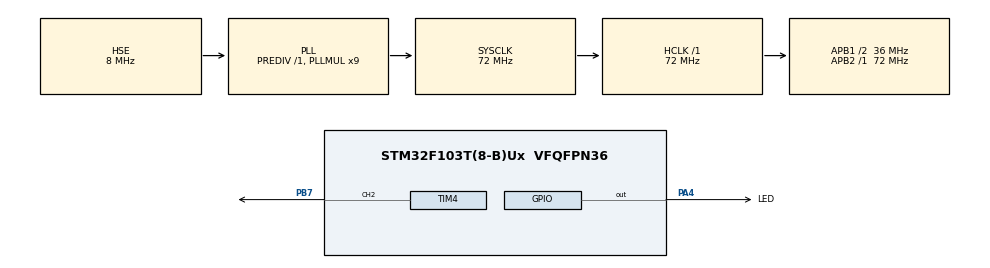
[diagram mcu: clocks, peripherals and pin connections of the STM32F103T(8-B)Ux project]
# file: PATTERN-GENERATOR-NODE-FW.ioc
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Mcu.Family=STM32F1
RCC.PLLSourceVirtual=RCC_PLLSOURCE_HSE
PD1-OSC_OUT.Mode=HSE-External-Oscillator
PD0-OSC_IN.Signal=RCC_OSC_IN
RCC.APB1CLKDivider=RCC_HCLK_DIV2
RCC.SYSCLKSource=RCC_SYSCLKSOURCE_PLLCLK
ProjectManager.StackSize=0x400
Dma.TIM4_CH2.0.PeriphInc=DMA_PINC_DISABLE
Dma.TIM4_CH2.0.Priority=DMA_PRIORITY_LOW
PD1-OSC_OUT.Signal=RCC_OSC_OUT
PA13.Signal=SYS_JTMS-SWDIO
ProjectManager.TargetToolchain=STM32CubeIDE
Dma.TIM4_CH2.0.MemInc=DMA_MINC_ENABLE
Dma.TIM4_CH2.0.Mode=DMA_NORMAL
RCC.HCLKFreq_Value=72000000
RCC.APB2TimFreq_Value=72000000
RCC.USBFreq_Value=72000000
Dma.TIM4_CH2.0.PeriphDataAlignment=DMA_PDATAALIGN_HALFWORD
RCC.AHBFreq_Value=72000000
PD0-OSC_IN.Mode=HSE-External-Oscillator
PB7.GPIO_ModeDefaultPP=GPIO_MODE_AF_PP
board=custom
RCC.PLLMUL=RCC_PLL_MUL9
TIM4.Channel-PWM\ Generation2\ CH2=TIM_CHANNEL_2
RCC.APB2Freq_Value=72000000
PA14.Mode=Serial_Wire
SH.S_TIM4_CH2.0=TIM4_CH2,PWM Generation2 CH2
PB7.Signal=S_TIM4_CH2
TIM4.Period=90
Dma.TIM4_CH2.0.Direction=DMA_MEMORY_TO_PERIPH
PA13.Mode=Serial_Wire
Mcu.Name=STM32F103T(8-B)Ux
PA4.Signal=GPIO_Output
RCC.SYSCLKFreq_VALUE=72000000
Mcu.Package=VFQFPN36
PA14.Signal=SYS_JTCK-SWCLK
ProjectManager.HeapSize=0x200
PA4.GPIO_ModeDefaultOutputPP=GPIO_MODE_OUTPUT_PP
VP_TIM4_VS_ClockSourceINT.Mode=Internal
NVIC.PriorityGroup=NVIC_PRIORITYGROUP_4
Dma.TIM4_CH2.0.Instance=DMA1_Channel4
RCC.APB1TimFreq_Value=72000000
NVIC.DMA1_Channel4_IRQn=true\:0\:0\:false\:false\:true\:false\:true
NVIC.TIM4_IRQn=true\:0\:0\:false\:false\:true\:true\:true
Dma.Request0=TIM4_CH2
RCC.APB1Freq_Value=36000000
PA4.GPIO_Label=LED
Dma.TIM4_CH2.0.MemDataAlignment=DMA_MDATAALIGN_HALFWORD
TIM4.Pulse-PWM\ Generation2\ CH2=45
PB7.GPIO_Speed=GPIO_SPEED_FREQ_LOW

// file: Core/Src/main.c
/* USER CODE BEGIN Header */
/**
  ******************************************************************************
  * @file           : main.c
  * @brief          : Main program body
  ******************************************************************************
  * @attention
  *
  * <h2><center>&copy; Copyright (c) 2021 STMicroelectronics.
  * All rights reserved.</center></h2>
  *
  * This software component is licensed by ST under BSD 3-Clause license,
  * the "License"; You may not use this file except in compliance with the
  * License. You may obtain a copy of the License at:
  *                        opensource.org/licenses/BSD-3-Clause
  *
  ******************************************************************************
  */
/* USER CODE END Header */
#include "main.h"

/* USER CODE BEGIN Includes */
#include "leds_rgb.h"
/* USER CODE END Includes */

TIM_HandleTypeDef htim4;
DMA_HandleTypeDef hdma_tim4_ch2;

void SystemClock_Config(void);
static void MX_GPIO_Init(void);
static void MX_DMA_Init(void);
static void MX_TIM4_Init(void);

/* USER CODE BEGIN 0 */
Leds_Color_t colors;
const uint32_t RGB_PALLET[MAX_NUM_OF_LEDS] = {
/*
 *    1		2		   3		4	    	5		6		7			8		9			10		11			12		  13		14		  15 		16
 */

0xff2828, 0xff7c28, 0xffd128, 0xebff28, 0x97ff28, 0x42ff28, 0x28ffb6, 0x28d5ff, 0x28b1ff, 0x285dff, 0x4828ff, 0x9c28ff, 0xf028ff, 0xff28cb, 0xff2877, 0xc1c1c1,//0
0xff2828, 0xff7c28, 0xffd128, 0xebff28, 0x97ff28, 0x42ff28, 0x28ffb6, 0x28d5ff, 0x28b1ff, 0x285dff, 0x4828ff, 0x9c28ff, 0xf028ff, 0xff28cb, 0xff2877, 0xc1c1c1,//1
0xff2828, 0xff7c28, 0xffd128, 0xebff28, 0x97ff28, 0x42ff28, 0x28ffb6, 0x28d5ff, 0x28b1ff, 0x285dff, 0x4828ff, 0x9c28ff, 0xf028ff, 0xff28cb, 0xff2877, 0xc1c1c1,//2
0xff2828, 0xff7c28, 0xffd128, 0xebff28, 0x97ff28, 0x42ff28, 0x28ffb6, 0x28d5ff, 0x28b1ff, 0x285dff, 0x4828ff, 0x9c28ff, 0xf028ff, 0xff28cb, 0xff2877, 0xc1c1c1,//3
0xff2828, 0xff7c28, 0xffd128, 0xebff28, 0x97ff28, 0x42ff28, 0x28ffb6, 0x28d5ff, 0x28b1ff, 0x285dff, 0x4828ff, 0x9c28ff, 0xf028ff, 0xff28cb, 0xff2877, 0xc1c1c1 //4
};

/* USER CODE END 0 */

int main(void)
{

  /* MCU Configuration--------------------------------------------------------*/

  /* Reset of all peripherals, Initializes the Flash interface and the Systick. */
  HAL_Init();

  /* Configure the system clock */
  SystemClock_Config();

  /* Initialize all configured peripherals */
  MX_GPIO_Init();
  MX_DMA_Init();
  MX_TIM4_Init();
  /* USER CODE BEGIN 2 */
  for (int var = 0; var < MAX_NUM_OF_LEDS; ++var) {
//	if((var%16)<4){
//	  	colors.colors[var].shades.red   = (uint8_t)((0xff0000 & 0xff0000)>>16);
//	  	colors.colors[var].shades.green = (uint8_t)((0x00ff00 & 0xff0000)>>8);
//	  	colors.colors[var].shades.blue  = (uint8_t)((0x0000ff & 0xff0000));
//	}
//	else

  	colors.colors[var].shades.red   = (uint8_t)((0xff0000 & RGB_PALLET[var])>>16);
  	colors.colors[var].shades.green = (uint8_t)((0x00ff00 & RGB_PALLET[var])>>8);
  	colors.colors[var].shades.blue  = (uint8_t)((0x0000ff & RGB_PALLET[var]));

  }
  if(rgbLedsInit(MAX_NUM_OF_LEDS, &htim4, TIM_CHANNEL_2)== STATUS_OK){
	  HAL_GPIO_TogglePin(LED_GPIO_Port, LED_Pin);
	  	  HAL_Delay(25);
	  	  HAL_GPIO_TogglePin(LED_GPIO_Port, LED_Pin);
	  	  HAL_Delay(25);
	  	  HAL_GPIO_TogglePin(LED_GPIO_Port, LED_Pin);
	  	  HAL_Delay(25);
	  	  HAL_GPIO_TogglePin(LED_GPIO_Port, LED_Pin);
	  	  HAL_Delay(25);
	  	  HAL_GPIO_TogglePin(LED_GPIO_Port, LED_Pin);
	  	  HAL_Delay(25);
	  	  HAL_GPIO_TogglePin(LED_GPIO_Port, LED_Pin);
	  	  HAL_Delay(25);
  }
  else{
	  for(;;){
	  	  HAL_GPIO_TogglePin(LED_GPIO_Port, LED_Pin);
	  	  HAL_Delay(25);
	  	  HAL_GPIO_TogglePin(LED_GPIO_Port, LED_Pin);
	  	  HAL_Delay(25);
	  	  HAL_GPIO_TogglePin(LED_GPIO_Port, LED_Pin);
	  	  HAL_Delay(25);
	  	  HAL_GPIO_TogglePin(LED_GPIO_Port, LED_Pin);

	  	  HAL_Delay(1000);
	  }
  }
  rgbLedsMapColorToPwm(&colors);
  /* USER CODE END 2 */

  /* Infinite loop */
  /* USER CODE BEGIN WHILE */

//  uint32_t colour = 0xff2828;  // colour code for some color
//  WS2812_Send(colour);

  while (1)
  {
    /* USER CODE END WHILE */

    /* USER CODE BEGIN 3 */
	  rgbLedsStart();
	  HAL_Delay(250);

  }
  /* USER CODE END 3 */
}

void SystemClock_Config(void)
{
  RCC_OscInitTypeDef RCC_OscInitStruct = {0};
  RCC_ClkInitTypeDef RCC_ClkInitStruct = {0};

  /** Initializes the RCC Oscillators according to the specified parameters
  * in the RCC_OscInitTypeDef structure.
  */
  RCC_OscInitStruct.OscillatorType = RCC_OSCILLATORTYPE_HSE;
  RCC_OscInitStruct.HSEState = RCC_HSE_ON;
  RCC_OscInitStruct.HSEPredivValue = RCC_HSE_PREDIV_DIV1;
  RCC_OscInitStruct.HSIState = RCC_HSI_ON;
  RCC_OscInitStruct.PLL.PLLState = RCC_PLL_ON;
  RCC_OscInitStruct.PLL.PLLSource = RCC_PLLSOURCE_HSE;
  RCC_OscInitStruct.PLL.PLLMUL = RCC_PLL_MUL9;
  if (HAL_RCC_OscConfig(&RCC_OscInitStruct) != HAL_OK)
  {
    Error_Handler();
  }
  /** Initializes the CPU, AHB and APB buses clocks
  */
  RCC_ClkInitStruct.ClockType = RCC_CLOCKTYPE_HCLK|RCC_CLOCKTYPE_SYSCLK
                              |RCC_CLOCKTYPE_PCLK1|RCC_CLOCKTYPE_PCLK2;
  RCC_ClkInitStruct.SYSCLKSource = RCC_SYSCLKSOURCE_PLLCLK;
  RCC_ClkInitStruct.AHBCLKDivider = RCC_SYSCLK_DIV1;
  RCC_ClkInitStruct.APB1CLKDivider = RCC_HCLK_DIV2;
  RCC_ClkInitStruct.APB2CLKDivider = RCC_HCLK_DIV1;

  if (HAL_RCC_ClockConfig(&RCC_ClkInitStruct, FLASH_LATENCY_2) != HAL_OK)
  {
    Error_Handler();
  }
}

static void MX_TIM4_Init(void)
{

  TIM_ClockConfigTypeDef sClockSourceConfig = {0};
  TIM_MasterConfigTypeDef sMasterConfig = {0};
  TIM_OC_InitTypeDef sConfigOC = {0};

  htim4.Instance = TIM4;
  htim4.Init.Prescaler = 0;
  htim4.Init.CounterMode = TIM_COUNTERMODE_UP;
  htim4.Init.Period = 90;
  htim4.Init.ClockDivision = TIM_CLOCKDIVISION_DIV1;
  htim4.Init.AutoReloadPreload = TIM_AUTORELOAD_PRELOAD_DISABLE;
  if (HAL_TIM_Base_Init(&htim4) != HAL_OK)
  {
    Error_Handler();
  }
  sClockSourceConfig.ClockSource = TIM_CLOCKSOURCE_INTERNAL;
  if (HAL_TIM_ConfigClockSource(&htim4, &sClockSourceConfig) != HAL_OK)
  {
    Error_Handler();
  }
  if (HAL_TIM_PWM_Init(&htim4) != HAL_OK)
  {
    Error_Handler();
  }
  sMasterConfig.MasterOutputTrigger = TIM_TRGO_RESET;
  sMasterConfig.MasterSlaveMode = TIM_MASTERSLAVEMODE_DISABLE;
  if (HAL_TIMEx_MasterConfigSynchronization(&htim4, &sMasterConfig) != HAL_OK)
  {
    Error_Handler();
  }
  sConfigOC.OCMode = TIM_OCMODE_PWM1;
  sConfigOC.Pulse = 45;
  sConfigOC.OCPolarity = TIM_OCPOLARITY_HIGH;
  sConfigOC.OCFastMode = TIM_OCFAST_DISABLE;
  if (HAL_TIM_PWM_ConfigChannel(&htim4, &sConfigOC, TIM_CHANNEL_2) != HAL_OK)
  {
    Error_Handler();
  }
  HAL_TIM_MspPostInit(&htim4);

}

static void MX_DMA_Init(void)
{

  /* DMA controller clock enable */
  __HAL_RCC_DMA1_CLK_ENABLE();

  /* DMA interrupt init */
  /* DMA1_Channel4_IRQn interrupt configuration */
  HAL_NVIC_SetPriority(DMA1_Channel4_IRQn, 0, 0);
  HAL_NVIC_EnableIRQ(DMA1_Channel4_IRQn);

}

static void MX_GPIO_Init(void)
{
  GPIO_InitTypeDef GPIO_InitStruct = {0};

  /* GPIO Ports Clock Enable */
  __HAL_RCC_GPIOD_CLK_ENABLE();
  __HAL_RCC_GPIOA_CLK_ENABLE();
  __HAL_RCC_GPIOB_CLK_ENABLE();

  /*Configure GPIO pin Output Level */
  HAL_GPIO_WritePin(LED_GPIO_Port, LED_Pin, GPIO_PIN_RESET);

  /*Configure GPIO pin : LED_Pin */
  GPIO_InitStruct.Pin = LED_Pin;
  GPIO_InitStruct.Mode = GPIO_MODE_OUTPUT_PP;
  GPIO_InitStruct.Pull = GPIO_NOPULL;
  GPIO_InitStruct.Speed = GPIO_SPEED_FREQ_LOW;
  HAL_GPIO_Init(LED_GPIO_Port, &GPIO_InitStruct);

}

void Error_Handler(void)
{
  __disable_irq();
  while (1)
  {
  }
}

/************************ (C) COPYRIGHT STMicroelectronics *****END OF FILE****/
